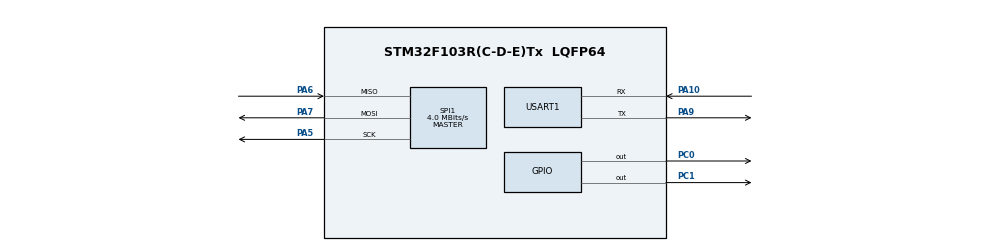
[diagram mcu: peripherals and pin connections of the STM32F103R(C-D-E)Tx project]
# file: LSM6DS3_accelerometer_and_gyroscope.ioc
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Mcu.Family=STM32F1
Mcu.Name=STM32F103R(C-D-E)Tx
Mcu.Package=LQFP64
NVIC.PriorityGroup=NVIC_PRIORITYGROUP_4
PA10.Mode=Asynchronous
PA10.Signal=USART1_RX
PA13.Mode=JTAG_5_pins
PA13.Signal=SYS_JTMS-SWDIO
PA14.Mode=JTAG_5_pins
PA14.Signal=SYS_JTCK-SWCLK
PA15.Mode=JTAG_5_pins
PA15.Signal=SYS_JTDI
PA5.Mode=Full_Duplex_Master
PA5.Signal=SPI1_SCK
PA6.Mode=Full_Duplex_Master
PA6.Signal=SPI1_MISO
PA7.Mode=Full_Duplex_Master
PA7.Signal=SPI1_MOSI
PA9.Mode=Asynchronous
PA9.Signal=USART1_TX
PB3.Mode=JTAG_5_pins
PB3.Signal=SYS_JTDO-TRACESWO
PB4.Mode=JTAG_5_pins
PB4.Signal=SYS_NJTRST
PC0.Signal=GPIO_Output
PC1.Signal=GPIO_Output
PD0-OSC_IN.Mode=HSE-External-Oscillator
PD0-OSC_IN.Signal=RCC_OSC_IN
PD1-OSC_OUT.Mode=HSE-External-Oscillator
PD1-OSC_OUT.Signal=RCC_OSC_OUT
ProjectManager.HeapSize=0x200
ProjectManager.StackSize=0x400
ProjectManager.TargetToolchain=MDK-ARM V5.27
RCC.AHBCLKDivider=RCC_SYSCLK_DIV2
RCC.AHBFreq_Value=8000000
RCC.APB1Freq_Value=8000000
RCC.APB1TimFreq_Value=8000000
RCC.APB2Freq_Value=8000000
RCC.APB2TimFreq_Value=8000000
RCC.HCLKFreq_Value=8000000
RCC.PLLSourceVirtual=RCC_PLLSOURCE_HSE
RCC.SYSCLKFreq_VALUE=16000000
RCC.SYSCLKSource=RCC_SYSCLKSOURCE_PLLCLK
RCC.USBFreq_Value=16000000
SPI1.BaudRatePrescaler=SPI_BAUDRATEPRESCALER_2
SPI1.CalculateBaudRate=4.0 MBits/s
SPI1.Direction=SPI_DIRECTION_2LINES
SPI1.Mode=SPI_MODE_MASTER
SPI1.VirtualType=VM_MASTER
USART1.VirtualMode=VM_ASYNC
board=custom

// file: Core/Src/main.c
/* USER CODE BEGIN Header */
/**
  ******************************************************************************
  * @file           : main.c
  * @brief          : Main program body
  ******************************************************************************
  * @attention
  *
  * <h2><center>&copy; Copyright (c) 2021 STMicroelectronics.
  * All rights reserved.</center></h2>
  *
  * This software component is licensed by ST under BSD 3-Clause license,
  * the "License"; You may not use this file except in compliance with the
  * License. You may obtain a copy of the License at:
  *                        opensource.org/licenses/BSD-3-Clause
  *
  ******************************************************************************
  */
/* USER CODE END Header */
#include "main.h"

/* USER CODE BEGIN Includes */
#include "stdio_usart1.h"
#include "stdio.h"
#include "LSM6DS3.h"
/* USER CODE END Includes */

void SystemClock_Config(void);
static void MX_GPIO_Init(void);
static void MX_SPI1_Init(void);
static void MX_USART1_UART_Init(void);

int main(void)
{

  /* MCU Configuration--------------------------------------------------------*/

  /* Reset of all peripherals, Initializes the Flash interface and the Systick. */

  LL_APB2_GRP1_EnableClock(LL_APB2_GRP1_PERIPH_AFIO);
  LL_APB1_GRP1_EnableClock(LL_APB1_GRP1_PERIPH_PWR);

  NVIC_SetPriorityGrouping(NVIC_PRIORITYGROUP_4);

  /* System interrupt init*/

  /** ENABLE: Full SWJ (JTAG-DP + SW-DP): Reset State
  */
  LL_GPIO_AF_EnableRemap_SWJ();

  /* Configure the system clock */
  SystemClock_Config();

  /* Initialize all configured peripherals */
  MX_GPIO_Init();
  MX_SPI1_Init();
  MX_USART1_UART_Init();
  /* USER CODE BEGIN 2 */
	/* enabling SPI1 unit and initializing LSM6DS3 module */
		LL_SPI_Enable(SPI1);
		LL_GPIO_SetOutputPin(GPIOC, LL_GPIO_PIN_0);

	  LL_mDelay(10);

		initialize_LSM6DS3();

  /* USER CODE END 2 */

  /* Infinite loop */
  while (1)
  {

    /* USER CODE BEGIN 3 */
LL_mDelay(250);

		/* print calibrated values of the Gyroscope and the Accelerometer */
		print_acc_cal();
		print_gyro_cal();

  }
  /* USER CODE END 3 */
}

void SystemClock_Config(void)
{
  LL_FLASH_SetLatency(LL_FLASH_LATENCY_0);
  while(LL_FLASH_GetLatency()!= LL_FLASH_LATENCY_0)
  {
  }
  LL_RCC_HSE_Enable();

   /* Wait till HSE is ready */
  while(LL_RCC_HSE_IsReady() != 1)
  {

  }
  LL_RCC_PLL_ConfigDomain_SYS(LL_RCC_PLLSOURCE_HSE_DIV_1, LL_RCC_PLL_MUL_2);
  LL_RCC_PLL_Enable();

   /* Wait till PLL is ready */
  while(LL_RCC_PLL_IsReady() != 1)
  {

  }
  LL_RCC_SetAHBPrescaler(LL_RCC_SYSCLK_DIV_2);
  LL_RCC_SetAPB1Prescaler(LL_RCC_APB1_DIV_1);
  LL_RCC_SetAPB2Prescaler(LL_RCC_APB2_DIV_1);
  LL_RCC_SetSysClkSource(LL_RCC_SYS_CLKSOURCE_PLL);

   /* Wait till System clock is ready */
  while(LL_RCC_GetSysClkSource() != LL_RCC_SYS_CLKSOURCE_STATUS_PLL)
  {

  }
  LL_Init1msTick(8000000);
  LL_SetSystemCoreClock(8000000);
}

static void MX_SPI1_Init(void)
{

  LL_SPI_InitTypeDef SPI_InitStruct = {0};

  LL_GPIO_InitTypeDef GPIO_InitStruct = {0};

  /* Peripheral clock enable */
  LL_APB2_GRP1_EnableClock(LL_APB2_GRP1_PERIPH_SPI1);

  LL_APB2_GRP1_EnableClock(LL_APB2_GRP1_PERIPH_GPIOA);
  /**SPI1 GPIO Configuration
  PA5   ------> SPI1_SCK
  PA6   ------> SPI1_MISO
  PA7   ------> SPI1_MOSI
  */
  GPIO_InitStruct.Pin = LL_GPIO_PIN_5|LL_GPIO_PIN_7;
  GPIO_InitStruct.Mode = LL_GPIO_MODE_ALTERNATE;
  GPIO_InitStruct.Speed = LL_GPIO_SPEED_FREQ_HIGH;
  GPIO_InitStruct.OutputType = LL_GPIO_OUTPUT_PUSHPULL;
  LL_GPIO_Init(GPIOA, &GPIO_InitStruct);

  GPIO_InitStruct.Pin = LL_GPIO_PIN_6;
  GPIO_InitStruct.Mode = LL_GPIO_MODE_FLOATING;
  LL_GPIO_Init(GPIOA, &GPIO_InitStruct);

  /* SPI1 parameter configuration*/
  SPI_InitStruct.TransferDirection = LL_SPI_FULL_DUPLEX;
  SPI_InitStruct.Mode = LL_SPI_MODE_MASTER;
  SPI_InitStruct.DataWidth = LL_SPI_DATAWIDTH_8BIT;
  SPI_InitStruct.ClockPolarity = LL_SPI_POLARITY_LOW;
  SPI_InitStruct.ClockPhase = LL_SPI_PHASE_1EDGE;
  SPI_InitStruct.NSS = LL_SPI_NSS_SOFT;
  SPI_InitStruct.BaudRate = LL_SPI_BAUDRATEPRESCALER_DIV2;
  SPI_InitStruct.BitOrder = LL_SPI_MSB_FIRST;
  SPI_InitStruct.CRCCalculation = LL_SPI_CRCCALCULATION_DISABLE;
  SPI_InitStruct.CRCPoly = 10;
  LL_SPI_Init(SPI1, &SPI_InitStruct);

}

static void MX_USART1_UART_Init(void)
{

  LL_USART_InitTypeDef USART_InitStruct = {0};

  LL_GPIO_InitTypeDef GPIO_InitStruct = {0};

  /* Peripheral clock enable */
  LL_APB2_GRP1_EnableClock(LL_APB2_GRP1_PERIPH_USART1);

  LL_APB2_GRP1_EnableClock(LL_APB2_GRP1_PERIPH_GPIOA);
  /**USART1 GPIO Configuration
  PA9   ------> USART1_TX
  PA10   ------> USART1_RX
  */
  GPIO_InitStruct.Pin = LL_GPIO_PIN_9;
  GPIO_InitStruct.Mode = LL_GPIO_MODE_ALTERNATE;
  GPIO_InitStruct.Speed = LL_GPIO_SPEED_FREQ_HIGH;
  GPIO_InitStruct.OutputType = LL_GPIO_OUTPUT_PUSHPULL;
  LL_GPIO_Init(GPIOA, &GPIO_InitStruct);

  GPIO_InitStruct.Pin = LL_GPIO_PIN_10;
  GPIO_InitStruct.Mode = LL_GPIO_MODE_FLOATING;
  LL_GPIO_Init(GPIOA, &GPIO_InitStruct);

  USART_InitStruct.BaudRate = 115200;
  USART_InitStruct.DataWidth = LL_USART_DATAWIDTH_8B;
  USART_InitStruct.StopBits = LL_USART_STOPBITS_1;
  USART_InitStruct.Parity = LL_USART_PARITY_NONE;
  USART_InitStruct.TransferDirection = LL_USART_DIRECTION_TX_RX;
  USART_InitStruct.HardwareFlowControl = LL_USART_HWCONTROL_NONE;
  USART_InitStruct.OverSampling = LL_USART_OVERSAMPLING_16;
  LL_USART_Init(USART1, &USART_InitStruct);
  LL_USART_ConfigAsyncMode(USART1);
  LL_USART_Enable(USART1);

}

static void MX_GPIO_Init(void)
{
  LL_GPIO_InitTypeDef GPIO_InitStruct = {0};

  /* GPIO Ports Clock Enable */
  LL_APB2_GRP1_EnableClock(LL_APB2_GRP1_PERIPH_GPIOD);
  LL_APB2_GRP1_EnableClock(LL_APB2_GRP1_PERIPH_GPIOC);
  LL_APB2_GRP1_EnableClock(LL_APB2_GRP1_PERIPH_GPIOA);
  LL_APB2_GRP1_EnableClock(LL_APB2_GRP1_PERIPH_GPIOB);

  /**/
  LL_GPIO_ResetOutputPin(GPIOC, LL_GPIO_PIN_0|LL_GPIO_PIN_1);

  /**/
  GPIO_InitStruct.Pin = LL_GPIO_PIN_0|LL_GPIO_PIN_1;
  GPIO_InitStruct.Mode = LL_GPIO_MODE_OUTPUT;
  GPIO_InitStruct.Speed = LL_GPIO_SPEED_FREQ_LOW;
  GPIO_InitStruct.OutputType = LL_GPIO_OUTPUT_PUSHPULL;
  LL_GPIO_Init(GPIOC, &GPIO_InitStruct);

}

void Error_Handler(void)
{
  __disable_irq();
  while (1)
  {
  }
}

/************************ (C) COPYRIGHT STMicroelectronics *****END OF FILE****/
